# ATSAM3U1E register map
Vendor: Atmel; Series: SAM3U; File version: 0
CPU: CM3 r2p0, selectable endian, MPU, no FPU, 4 interrupt priority bits
Registers are 32-bit, read-write, reset 0x0 unless marked. A register's access mark holds for its fields unless they carry their own. Offsets are from the block's base; [hi:lo] are bit positions; {n}, {i} and the like mark numbered series.

## UDPHS — USB High Speed Device Port
Base 0x400A4000; register names take the prefix UDPHS_
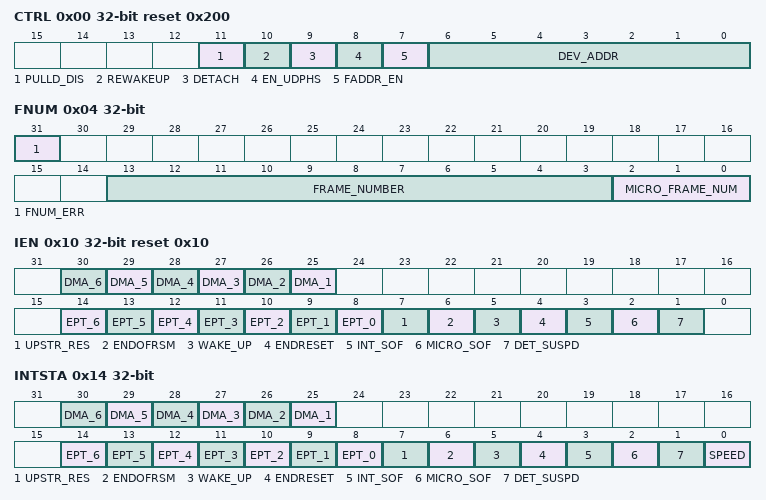
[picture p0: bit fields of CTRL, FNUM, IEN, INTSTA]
0x00 CTRL reset 0x200 — UDPHS Control Register
  [11] PULLD_DIS — Pull-Down Disable
  [10] REWAKEUP — Send Remote Wake Up
  [9] DETACH — Detach Command
  [8] EN_UDPHS — UDPHS Enable
  [7] FADDR_EN — Function Address Enable
  [6:0] DEV_ADDR — UDPHS Address
0x04 FNUM ro — UDPHS Frame Number Register
  [31] FNUM_ERR — Frame Number CRC Error
  [13:3] FRAME_NUMBER — Frame Number as defined in the Packet Field Formats
  [2:0] MICRO_FRAME_NUM — Microframe Number
0x10 IEN reset 0x10 — UDPHS Interrupt Enable Register
  [n+24] DMA_{n} (n=1..6) — DMA Channel {n} Interrupt Enable
  [n+8] EPT_{n} (n=0..6) — Endpoint {n} Interrupt Enable
  [7] UPSTR_RES — Upstream Resume Interrupt Enable
  [6] ENDOFRSM — End Of Resume Interrupt Enable
  [5] WAKE_UP — Wake Up CPU Interrupt Enable
  [4] ENDRESET — End Of Reset Interrupt Enable
  [3] INT_SOF — SOF Interrupt Enable
  [2] MICRO_SOF — Micro-SOF Interrupt Enable
  [1] DET_SUSPD — Suspend Interrupt Enable
0x14 INTSTA ro — UDPHS Interrupt Status Register
  [n+24] DMA_{n} (n=1..6) — DMA Channel {n} Interrupt
  [n+8] EPT_{n} (n=0..6) — Endpoint {n} Interrupt
  [7] UPSTR_RES — Upstream Resume Interrupt
  [6] ENDOFRSM — End Of Resume Interrupt
  [5] WAKE_UP — Wake Up CPU Interrupt
  [4] ENDRESET — End Of Reset Interrupt
  [3] INT_SOF — Start Of Frame Interrupt
  [2] MICRO_SOF — Micro Start Of Frame Interrupt
  [1] DET_SUSPD — Suspend Interrupt
  [0] SPEED — Speed Status
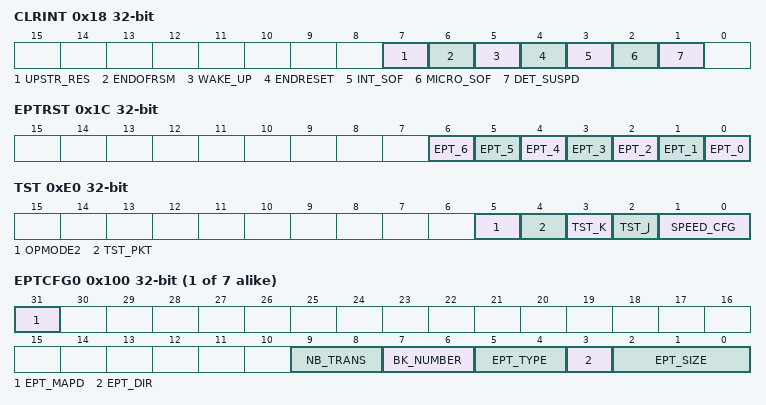
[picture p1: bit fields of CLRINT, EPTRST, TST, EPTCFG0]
0x18 CLRINT wo reset not defined — UDPHS Clear Interrupt Register
  [7] UPSTR_RES — Upstream Resume Interrupt Clear
  [6] ENDOFRSM — End Of Resume Interrupt Clear
  [5] WAKE_UP — Wake Up CPU Interrupt Clear
  [4] ENDRESET — End Of Reset Interrupt Clear
  [3] INT_SOF — Start Of Frame Interrupt Clear
  [2] MICRO_SOF — Micro Start Of Frame Interrupt Clear
  [1] DET_SUSPD — Suspend Interrupt Clear
0x1C EPTRST wo reset not defined — UDPHS Endpoints Reset Register
  [n] EPT_{n} (n=0..6) — Endpoint {n} Reset
0xE0 TST — UDPHS Test Register
  [5] OPMODE2
  [4] TST_PKT — Test Packet Mode
  [3] TST_K — Test K Mode
  [2] TST_J — Test J Mode
  [1:0] SPEED_CFG — Speed Configuration
    0=NORMAL (Normal Mode: The macro is in Full Speed mode, ready to make a High Speed identification, if the host supports it and then to automatically switch to High Speed mode); 2=HIGH_SPEED (Force High Speed: Set this value to force the hardware to work in High Speed mode. Only for debug or test purpose.); 3=FULL_SPEED (Force Full Speed: Set this value to force the hardware to work only in Full Speed mode. In this configuration, the macro will not respond to a High Speed reset handshake.)
{0x100+0x20*i} EPTCFG{i} (i=0..6) — UDPHS Endpoint Configuration Register (endpoint = {i})
  [31] EPT_MAPD — Endpoint Mapped
  [9:8] NB_TRANS — Number Of Transaction per Microframe
  [7:6] BK_NUMBER — Number of Banks
    0=Zero bank, the endpoint is not mapped in memory; 1=One bank (bank 0); 2=Double bank (Ping-Pong: bank0/bank1); 3=Triple bank (bank0/bank1/bank2)
  [5:4] EPT_TYPE — Endpoint Type
    0=CTRL8 (Control endpoint); 1=ISO (Isochronous endpoint); 2=BULK (Bulk endpoint); 3=INT (Interrupt endpoint)
  [3] EPT_DIR — Endpoint Direction
  [2:0] EPT_SIZE — Endpoint Size
    0=8 bytes; 1=16 bytes; 2=32 bytes; 3=64 bytes; 4=128 bytes; 5=256 bytes; 6=512 bytes; 7=1024 bytes
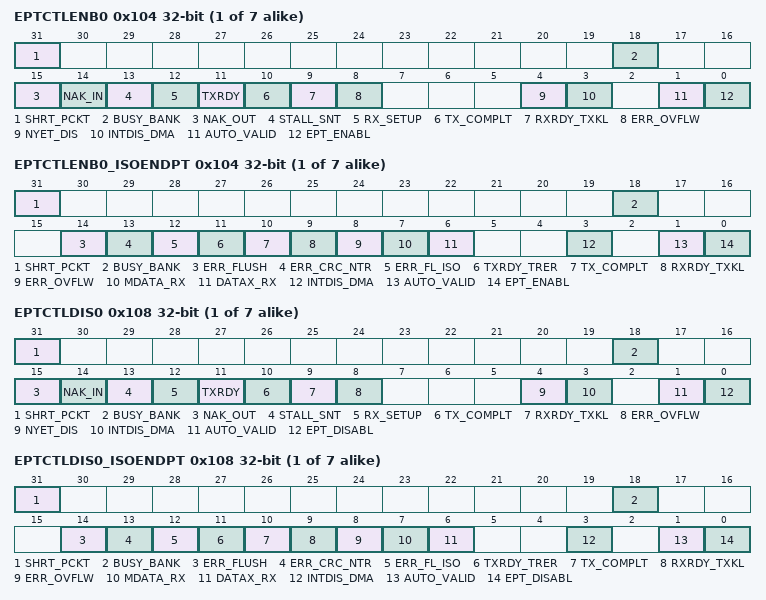
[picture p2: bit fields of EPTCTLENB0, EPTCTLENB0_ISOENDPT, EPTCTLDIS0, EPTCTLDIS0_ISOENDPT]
{0x104+0x20*i} EPTCTLENB{i} wo reset not defined (i=0..6) — UDPHS Endpoint Control Enable Register (endpoint = {i})
  [31] SHRT_PCKT — Short Packet Send/Short Packet Interrupt Enable
  [18] BUSY_BANK — Busy Bank Interrupt Enable
  [15] NAK_OUT — NAKOUT Interrupt Enable
  [14] NAK_IN — NAKIN Interrupt Enable
  [13] STALL_SNT — Stall Sent Interrupt Enable
  [12] RX_SETUP — Received SETUP
  [11] TXRDY — TX Packet Ready Interrupt Enable
  [10] TX_COMPLT — Transmitted IN Data Complete Interrupt Enable
  [9] RXRDY_TXKL — Received OUT Data Interrupt Enable
  [8] ERR_OVFLW — Overflow Error Interrupt Enable
  [4] NYET_DIS — NYET Disable (Only for High Speed Bulk OUT endpoints)
  [3] INTDIS_DMA — Interrupts Disable DMA
  [1] AUTO_VALID — Packet Auto-Valid Enable
  [0] EPT_ENABL — Endpoint Enable
{0x104+0x20*i} EPTCTLENB{i}_ISOENDPT wo reset not defined (ISOENDPT view) (i=0..6) — UDPHS Endpoint Control Enable Register (endpoint = {i})
  [31] SHRT_PCKT — Short Packet Send/Short Packet Interrupt Enable
  [18] BUSY_BANK — Busy Bank Interrupt Enable
  [14] ERR_FLUSH — Bank Flush Error Interrupt Enable
  [13] ERR_CRC_NTR — ISO CRC Error/Number of Transaction Error Interrupt Enable
  [12] ERR_FL_ISO — Error Flow Interrupt Enable
  [11] TXRDY_TRER — TX Packet Ready/Transaction Error Interrupt Enable
  [10] TX_COMPLT — Transmitted IN Data Complete Interrupt Enable
  [9] RXRDY_TXKL — Received OUT Data Interrupt Enable
  [8] ERR_OVFLW — Overflow Error Interrupt Enable
  [7] MDATA_RX — MDATA Interrupt Enable (Only for high bandwidth Isochronous OUT endpoints)
  [6] DATAX_RX — DATAx Interrupt Enable (Only for high bandwidth Isochronous OUT endpoints)
  [3] INTDIS_DMA — Interrupts Disable DMA
  [1] AUTO_VALID — Packet Auto-Valid Enable
  [0] EPT_ENABL — Endpoint Enable
{0x108+0x20*i} EPTCTLDIS{i} wo reset not defined (i=0..6) — UDPHS Endpoint Control Disable Register (endpoint = {i})
  [31] SHRT_PCKT — Short Packet Interrupt Disable
  [18] BUSY_BANK — Busy Bank Interrupt Disable
  [15] NAK_OUT — NAKOUT Interrupt Disable
  [14] NAK_IN — NAKIN Interrupt Disable
  [13] STALL_SNT — Stall Sent Interrupt Disable
  [12] RX_SETUP — Received SETUP Interrupt Disable
  [11] TXRDY — TX Packet Ready Interrupt Disable
  [10] TX_COMPLT — Transmitted IN Data Complete Interrupt Disable
  [9] RXRDY_TXKL — Received OUT Data Interrupt Disable
  [8] ERR_OVFLW — Overflow Error Interrupt Disable
  [4] NYET_DIS — NYET Enable (Only for High Speed Bulk OUT endpoints)
  [3] INTDIS_DMA — Interrupts Disable DMA
  [1] AUTO_VALID — Packet Auto-Valid Disable
  [0] EPT_DISABL — Endpoint Disable
{0x108+0x20*i} EPTCTLDIS{i}_ISOENDPT wo reset not defined (ISOENDPT view) (i=0..6) — UDPHS Endpoint Control Disable Register (endpoint = {i})
  [31] SHRT_PCKT — Short Packet Interrupt Disable
  [18] BUSY_BANK — Busy Bank Interrupt Disable
  [14] ERR_FLUSH — bank flush error Interrupt Disable
  [13] ERR_CRC_NTR — ISO CRC Error/Number of Transaction Error Interrupt Disable
  [12] ERR_FL_ISO — Error Flow Interrupt Disable
  [11] TXRDY_TRER — TX Packet Ready/Transaction Error Interrupt Disable
  [10] TX_COMPLT — Transmitted IN Data Complete Interrupt Disable
  [9] RXRDY_TXKL — Received OUT Data Interrupt Disable
  [8] ERR_OVFLW — Overflow Error Interrupt Disable
  [7] MDATA_RX — MDATA Interrupt Disable (Only for High Bandwidth Isochronous OUT endpoints)
  [6] DATAX_RX — DATAx Interrupt Disable (Only for High Bandwidth Isochronous OUT endpoints)
  [3] INTDIS_DMA — Interrupts Disable DMA
  [1] AUTO_VALID — Packet Auto-Valid Disable
  [0] EPT_DISABL — Endpoint Disable
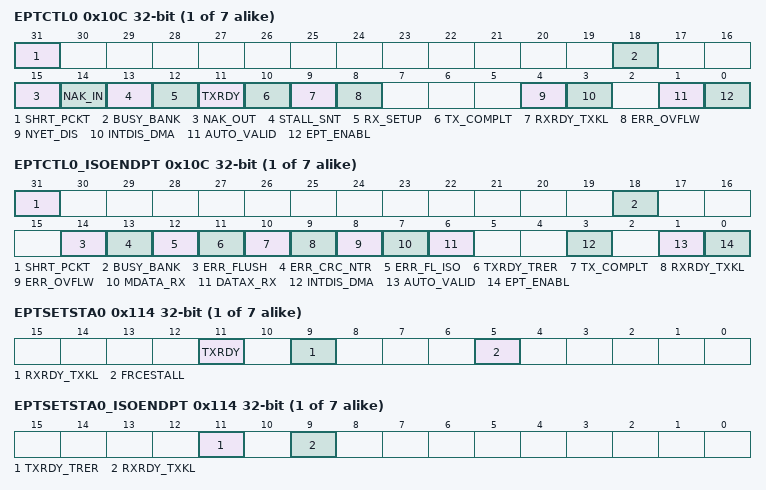
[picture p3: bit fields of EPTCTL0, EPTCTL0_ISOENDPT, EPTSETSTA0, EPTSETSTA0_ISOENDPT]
{0x10C+0x20*i} EPTCTL{i} ro (i=0..6) — UDPHS Endpoint Control Register (endpoint = {i})
  [31] SHRT_PCKT — Short Packet Interrupt Enabled
  [18] BUSY_BANK — Busy Bank Interrupt Enabled
  [15] NAK_OUT — NAKOUT Interrupt Enabled
  [14] NAK_IN — NAKIN Interrupt Enabled
  [13] STALL_SNT — Stall Sent Interrupt Enabled
  [12] RX_SETUP — Received SETUP Interrupt Enabled
  [11] TXRDY — TX Packet Ready Interrupt Enabled
  [10] TX_COMPLT — Transmitted IN Data Complete Interrupt Enabled
  [9] RXRDY_TXKL — Received OUT Data Interrupt Enabled
  [8] ERR_OVFLW — Overflow Error Interrupt Enabled
  [4] NYET_DIS — NYET Disable (Only for High Speed Bulk OUT endpoints)
  [3] INTDIS_DMA — Interrupt Disables DMA
  [1] AUTO_VALID — Packet Auto-Valid Enabled (Not for CONTROL Endpoints)
  [0] EPT_ENABL — Endpoint Enable
{0x10C+0x20*i} EPTCTL{i}_ISOENDPT ro (ISOENDPT view) (i=0..6) — UDPHS Endpoint Control Register (endpoint = {i})
  [31] SHRT_PCKT — Short Packet Interrupt Enabled
  [18] BUSY_BANK — Busy Bank Interrupt Enabled
  [14] ERR_FLUSH — Bank Flush Error Interrupt Enabled
  [13] ERR_CRC_NTR — ISO CRC Error/Number of Transaction Error Interrupt Enabled
  [12] ERR_FL_ISO — Error Flow Interrupt Enabled
  [11] TXRDY_TRER — TX Packet Ready/Transaction Error Interrupt Enabled
  [10] TX_COMPLT — Transmitted IN Data Complete Interrupt Enabled
  [9] RXRDY_TXKL — Received OUT Data Interrupt Enabled
  [8] ERR_OVFLW — Overflow Error Interrupt Enabled
  [7] MDATA_RX — MDATA Interrupt Enabled (Only for High Bandwidth Isochronous OUT endpoints)
  [6] DATAX_RX — DATAx Interrupt Enabled (Only for High Bandwidth Isochronous OUT endpoints)
  [3] INTDIS_DMA — Interrupt Disables DMA
  [1] AUTO_VALID — Packet Auto-Valid Enabled
  [0] EPT_ENABL — Endpoint Enable
{0x114+0x20*i} EPTSETSTA{i} wo reset not defined (i=0..6) — UDPHS Endpoint Set Status Register (endpoint = {i})
  [11] TXRDY — TX Packet Ready Set
  [9] RXRDY_TXKL — KILL Bank Set (for IN Endpoint)
  [5] FRCESTALL — Stall Handshake Request Set
{0x114+0x20*i} EPTSETSTA{i}_ISOENDPT wo reset not defined (ISOENDPT view) (i=0..6) — UDPHS Endpoint Set Status Register (endpoint = {i})
  [11] TXRDY_TRER — TX Packet Ready Set
  [9] RXRDY_TXKL — KILL Bank Set (for IN Endpoint)
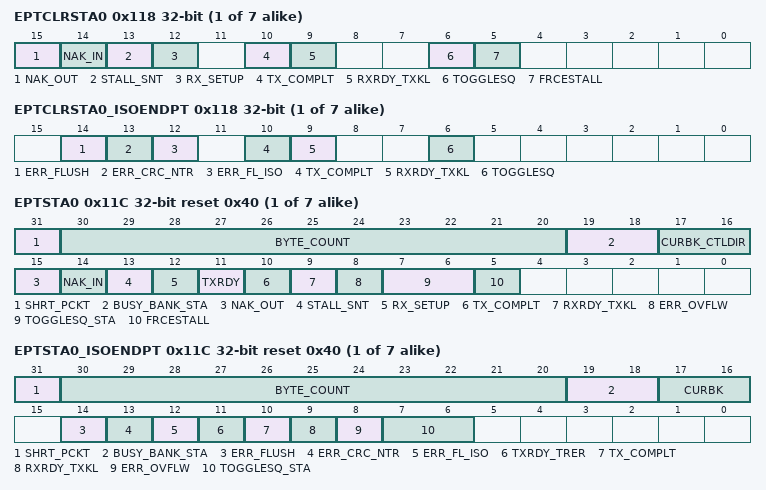
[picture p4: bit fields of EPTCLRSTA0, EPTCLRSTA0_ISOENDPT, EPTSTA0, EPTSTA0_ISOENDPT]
{0x118+0x20*i} EPTCLRSTA{i} wo reset not defined (i=0..6) — UDPHS Endpoint Clear Status Register (endpoint = {i})
  [15] NAK_OUT — NAKOUT Clear
  [14] NAK_IN — NAKIN Clear
  [13] STALL_SNT — Stall Sent Clear
  [12] RX_SETUP — Received SETUP Clear
  [10] TX_COMPLT — Transmitted IN Data Complete Clear
  [9] RXRDY_TXKL — Received OUT Data Clear
  [6] TOGGLESQ — Data Toggle Clear
  [5] FRCESTALL — Stall Handshake Request Clear
{0x118+0x20*i} EPTCLRSTA{i}_ISOENDPT wo reset not defined (ISOENDPT view) (i=0..6) — UDPHS Endpoint Clear Status Register (endpoint = {i})
  [14] ERR_FLUSH — Bank Flush Error Clear
  [13] ERR_CRC_NTR — Number of Transaction Error Clear
  [12] ERR_FL_ISO — Error Flow Clear
  [10] TX_COMPLT — Transmitted IN Data Complete Clear
  [9] RXRDY_TXKL — Received OUT Data Clear
  [6] TOGGLESQ — Data Toggle Clear
{0x11C+0x20*i} EPTSTA{i} ro reset 0x40 (i=0..6) — UDPHS Endpoint Status Register (endpoint = {i})
  [31] SHRT_PCKT — Short Packet
  [30:20] BYTE_COUNT — UDPHS Byte Count
  [19:18] BUSY_BANK_STA — Busy Bank Number
    0=1BUSYBANK; 1=2BUSYBANKS; 2=3BUSYBANKS
  [17:16] CURBK_CTLDIR — Current Bank/Control Direction
  [15] NAK_OUT
  [14] NAK_IN
  [13] STALL_SNT — Stall Sent
  [12] RX_SETUP — Received SETUP
  [11] TXRDY — TX Packet Ready
  [10] TX_COMPLT — Transmitted IN Data Complete
  [9] RXRDY_TXKL — Received OUT Data/KILL Bank
  [8] ERR_OVFLW — Overflow Error
  [7:6] TOGGLESQ_STA — Toggle Sequencing
    0=DATA0; 1=DATA1; 2=DATA2 (Reserved for High Bandwidth Isochronous Endpoint); 3=MDATA (Reserved for High Bandwidth Isochronous Endpoint)
  [5] FRCESTALL — Stall Handshake Request
{0x11C+0x20*i} EPTSTA{i}_ISOENDPT ro reset 0x40 (ISOENDPT view) (i=0..6) — UDPHS Endpoint Status Register (endpoint = {i})
  [31] SHRT_PCKT — Short Packet
  [30:20] BYTE_COUNT — UDPHS Byte Count
  [19:18] BUSY_BANK_STA — Busy Bank Number
    0=1BUSYBANK; 1=2BUSYBANKS; 2=3BUSYBANKS
  [17:16] CURBK — Current Bank
    0=BANK0 (Bank 0 (or single bank)); 1=BANK1; 2=BANK2
  [14] ERR_FLUSH — Bank Flush Error
  [13] ERR_CRC_NTR — CRC ISO Error/Number of Transaction Error
  [12] ERR_FL_ISO — Error Flow
  [11] TXRDY_TRER — TX Packet Ready/Transaction Error
  [10] TX_COMPLT — Transmitted IN Data Complete
  [9] RXRDY_TXKL — Received OUT Data/KILL Bank
  [8] ERR_OVFLW — Overflow Error
  [7:6] TOGGLESQ_STA — Toggle Sequencing
    0=DATA0; 1=DATA1; 2=DATA2 (Data2 (only for High Bandwidth Isochronous Endpoint)); 3=MDATA (MData (only for High Bandwidth Isochronous Endpoint))
{0x300+0x10*i} DMANXTDSC{i} (i=0..5) — UDPHS DMA Next Descriptor Address Register (channel = {i})
  [31:0] NXT_DSC_ADD — Next Descriptor Address
{0x304+0x10*i} DMAADDRESS{i} (i=0..5) — UDPHS DMA Channel Address Register (channel = {i})
  [31:0] BUFF_ADD — Buffer Address
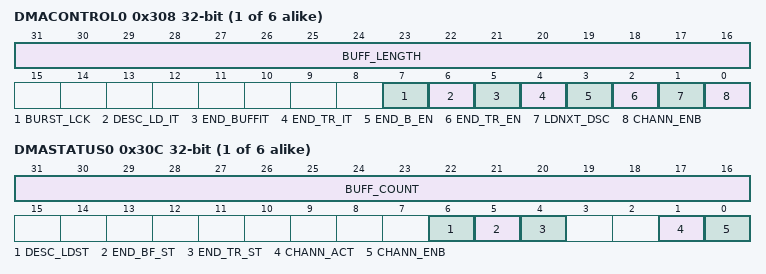
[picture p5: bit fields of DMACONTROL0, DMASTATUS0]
{0x308+0x10*i} DMACONTROL{i} (i=0..5) — UDPHS DMA Channel Control Register (channel = {i})
  [31:16] BUFF_LENGTH — Buffer Byte Length (Write-only)
  [7] BURST_LCK — Burst Lock Enable
  [6] DESC_LD_IT — Descriptor Loaded Interrupt Enable
  [5] END_BUFFIT — End of Buffer Interrupt Enable
  [4] END_TR_IT — End of Transfer Interrupt Enable
  [3] END_B_EN — End of Buffer Enable (Control)
  [2] END_TR_EN — End of Transfer Enable (Control)
  [1] LDNXT_DSC — Load Next Channel Transfer Descriptor Enable (Command)
  [0] CHANN_ENB — (Channel Enable Command)
{0x30C+0x10*i} DMASTATUS{i} (i=0..5) — UDPHS DMA Channel Status Register (channel = {i})
  [31:16] BUFF_COUNT — Buffer Byte Count
  [6] DESC_LDST — Descriptor Loaded Status
  [5] END_BF_ST — End of Channel Buffer Status
  [4] END_TR_ST — End of Channel Transfer Status
  [1] CHANN_ACT — Channel Active Status
  [0] CHANN_ENB — Channel Enable Status

## Notices in the file
SAM Software Package License
Copyright (c) 2014, Atmel Corporation
All rights reserved.
Redistribution and use in source and binary forms, with or without
modification, are permitted provided that the following condition is met:
- Redistributions of source code must retain the above copyright notice,
this list of conditions and the disclaimer below.
Atmel's name may not be used to endorse or promote products derived from
this software without specific prior written permission.
DISCLAIMER:  THIS SOFTWARE IS PROVIDED BY ATMEL "AS IS" AND ANY EXPRESS OR
IMPLIED WARRANTIES, INCLUDING, BUT NOT LIMITED TO, THE IMPLIED WARRANTIES OF
MERCHANTABILITY, FITNESS FOR A PARTICULAR PURPOSE AND NON-INFRINGEMENT ARE
DISCLAIMED. IN NO EVENT SHALL ATMEL BE LIABLE FOR ANY DIRECT, INDIRECT,
INCIDENTAL, SPECIAL, EXEMPLARY, OR CONSEQUENTIAL DAMAGES (INCLUDING, BUT NOT
LIMITED TO, PROCUREMENT OF SUBSTITUTE GOODS OR SERVICES; LOSS OF USE, DATA,
OR PROFITS; OR BUSINESS INTERRUPTION) HOWEVER CAUSED AND ON ANY THEORY OF
LIABILITY, WHETHER IN CONTRACT, STRICT LIABILITY, OR TORT (INCLUDING
NEGLIGENCE OR OTHERWISE) ARISING IN ANY WAY OUT OF THE USE OF THIS SOFTWARE,
EVEN IF ADVISED OF THE POSSIBILITY OF SUCH DAMAGE.
